# ADuCM322i register map
Vendor: Analog Devices Inc.; Series: ARMCM3; File version: 1.0
CPU: CM3 r2p1, little endian, no MPU, no FPU, 3 interrupt priority bits
Registers are 16-bit, read-write, no defined reset value unless marked. A register's access mark holds for its fields unless they carry their own. Offsets are from the block's base; [hi:lo] are bit positions; {n}, {i} and the like mark numbered series.

## GPIO0 — General Purpose Input Output 0
Base 0x40020000
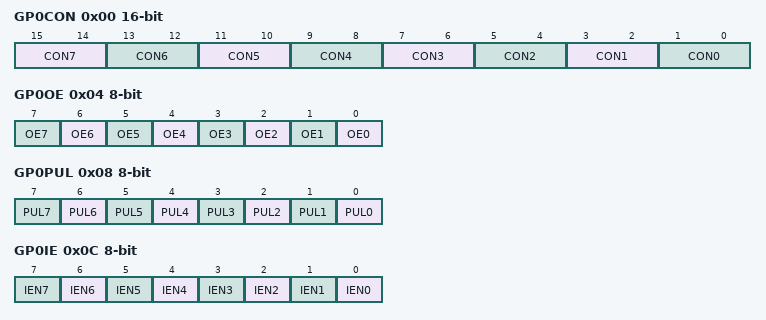
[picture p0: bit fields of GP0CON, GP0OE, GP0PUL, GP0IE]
0x00 GP0CON — GPIO Port 0 configuration
  [15:14] CON7 — p0.7 configuration bits
    0=GPIO; 1=I2C1SDA; 3=PLAO3
  [13:12] CON6 — p0.6 configuration bits
    0=GPIO; 1=I2C1SCL; 3=PLAO2
  [11:10] CON5 — p0.5 configuration bits
    0=GPIO; 1=I2C0SDA; 3=PLAO1
  [9:8] CON4 — p0.4 configuration bits
    0=GPIO; 1=I2CSCL (I2C0 SCL); 3=PLAO0
  [7:6] CON3 — p0.3 configuration bits
    0=GPIOIRQ0; 1=SPI0CS; 2=PLACLK0; 3=PLAI3
  [5:4] CON2 — p0.2 configuration bits
    0=GPIO; 1=SPI0MOSI; 3=PLAI2
  [3:2] CON1 — p0.1 configuration bits
    0=GPIO; 1=SIP0MISO (SPI0 MISO); 3=PLAI1
  [1:0] CON0 — p0.0 configuration bits
    0=GPIO; 1=SPI0SCLK; 3=PLAI0
0x04 GP0OE 8-bit — GPIO Port 0 output enable
  [all] fields
    0=DIS; 1=EN
  [n] OE{n} (n=0..7) — Pin output drive enable
0x08 GP0PUL 8-bit — GPIO Port 0 pullup enable
  [all] fields
    0=DIS; 1=EN
  [n] PUL{n} (n=0..7) — Pin Pull up enable
0x0C GP0IE 8-bit — GPIO Port 0 input path enable
  [all] fields
    0=DIS; 1=EN
  [n] IEN{n} (n=0..7) — Input path enable
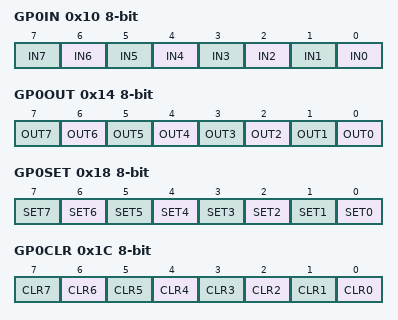
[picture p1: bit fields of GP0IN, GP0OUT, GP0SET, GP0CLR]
0x10 GP0IN 8-bit ro — GPIO Port 0 registered data input
  [all] fields
    0=LOW; 1=HIGH
  [n] IN{n} (n=0..7) — Registered data input
0x14 GP0OUT 8-bit — GPIO Port 0 data output
  [all] fields
    0=LOW; 1=HIGH
  [n] OUT{n} (n=0..7) — Data out
0x18 GP0SET 8-bit wo — GPIO Port 0 data out set
  [all] fields
    1=SET
  [n] SET{n} (n=0..7) — Set the output high.
0x1C GP0CLR 8-bit wo — GPIO Port 0 data out clear
  [all] fields
    1=CLR
  [n] CLR{n} (n=0..7) — Set the output low.
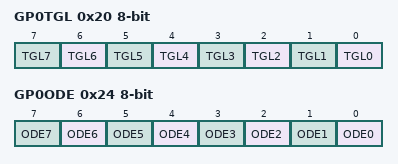
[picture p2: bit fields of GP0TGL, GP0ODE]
0x20 GP0TGL 8-bit wo — GPIO Port 0 pin toggle
  [all] fields
    1=TGL
  [n] TGL{n} (n=0..7) — Toggle the output of the port pin
0x24 GP0ODE 8-bit — GPIO Port 0 open drain enable
  [all] fields
    0=DIS; 1=EN
  [n] ODE{n} (n=0..7) — Open drain enable

## GPIO1 — General Purpose Input Output 1
Base 0x40020040
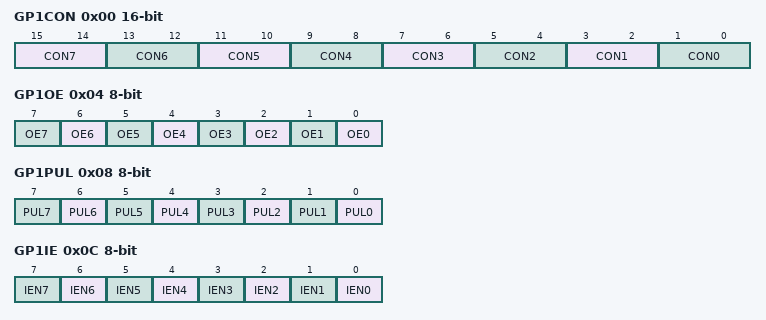
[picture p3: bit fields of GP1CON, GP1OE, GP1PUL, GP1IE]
0x00 GP1CON — GPIO Port 1 configuration
  [15:14] CON7 — p1.7 configuration bits
    0=GPIOIRQ1; 1=PWM5; 2=SPI1CS; 3=PLAO7
  [13:12] CON6 — p1.6 configuration bits
    0=GPIO; 1=PWM4; 2=SPI1MOSI; 3=PLAO6
  [11:10] CON5 — p1.5 configuration bits
    0=GPIO; 1=PWM3; 2=SPI1MISO; 3=PLAO5
  [9:8] CON4 — p1.4 configuration bits
    0=GPIO; 1=PWM2; 2=SPISCLK (SPI1 SCLK); 3=PLAO4
  [7:6] CON3 — p1.3 configuration bits
    0=GPIO; 1=PWM1; 3=PLAI7
  [5:4] CON2 — p1.2 configuration bits
    0=GPIO; 1=PWM0; 3=PLAI6
  [3:2] CON1 — p1.1 configuration bits
    0=GPIO; 1=UARTSOUT; 2=PLACLK1; 3=PLAI5
  [1:0] CON0 — p1.0 configuration bits
    0=GPIO; 1=UARTSIN; 2=ECLKIN (External Clock Input); 3=PLAI4
0x04 GP1OE 8-bit — GPIO Port 1 output enable
  [all] fields
    0=DIS; 1=EN
  [n] OE{n} (n=0..7) — Pin Output Drive enable
0x08 GP1PUL 8-bit — GPIO Port 1 pullup enable
  [all] fields
    0=DIS; 1=EN
  [n] PUL{n} (n=0..7) — Pin Pull up enable
0x0C GP1IE 8-bit — GPIO Port 1 input path enable
  [all] fields
    0=DIS; 1=EN
  [n] IEN{n} (n=0..7) — Input path enable
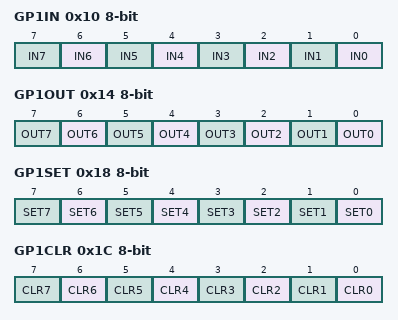
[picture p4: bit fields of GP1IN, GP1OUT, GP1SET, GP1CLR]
0x10 GP1IN 8-bit ro — GPIO Port 1 registered data input
  [all] fields
    0=LOW; 1=HIGH
  [n] IN{n} (n=0..7) — Registered data input
0x14 GP1OUT 8-bit — GPIO Port 1 data output
  [all] fields
    0=LOW; 1=HIGH
  [n] OUT{n} (n=0..7) — Data out
0x18 GP1SET 8-bit wo — GPIO Port 1 data out set
  [all] fields
    1=SET
  [n] SET{n} (n=0..7) — Set the output HIGH for the pin
0x1C GP1CLR 8-bit wo — GPIO Port 1 data out clear
  [all] fields
    1=CLR
  [n] CLR{n} (n=0..7) — Set the output low for the port pin
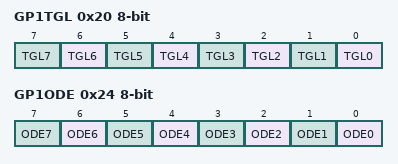
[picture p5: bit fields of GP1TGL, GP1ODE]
0x20 GP1TGL 8-bit wo — GPIO Port 1 pin toggle
  [all] fields
    1=TGL
  [n] TGL{n} (n=0..7) — Toggle the output of the port pin
0x24 GP1ODE 8-bit — GPIO Port 1 open drain enable
  [all] fields
    0=DIS; 1=EN
  [n] ODE{n} (n=0..7) — Open drain enable
